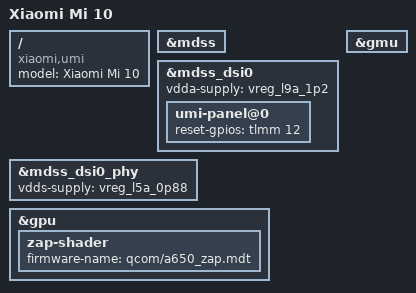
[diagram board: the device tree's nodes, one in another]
// SPDX-License-Identifier: BSD-3-Clause
/*
 * Xiaomi Mi 10 (umi / M2001J2C) — SM8250
 *
 * 阶段一（已完成）：内核能起来、USB 能枚举、COM3 拿到 root shell、UFS 6 个 LUN 全在。
 *   那时候故意不打开 mdss，让 simpledrm 接管 ABL 留下的 cont-splash，
 *   屏幕上能直接看到内核 log —— 没有 UART 时这是唯一可靠的观测手段。
 *
 * 阶段二（当前）：打开 mdss / DPU / DSI0 / 7nm PHY，验证显示子系统能 probe。
 *   ★ 面板节点（dts/xiaomi-umi-panels.dtsi）**默认不 include**。
 *     没有 panel 就：
 *       - devm_drm_of_get_bridge() 返回 -ENODEV
 *       - dsi_bind() 失败 -> msm master bind 失败 -> 不注册 card0
 *       - 因此不会做任何 modeset，屏幕上的 log 和以前完全一样
 *     但 DPU 的 dpu_kms_init()（读 catalog / 开 DISP_CC GDSC / 上 MMCX /
 *     读 MDP 寄存器）在 component_bind_all() **之前**就已经跑完了，
 *     所以这一次启动就能确认 mdss + DPU + DSI + PHY 的电源/时钟/寄存器通路。
 *
 * 阶段三：把文件末尾的 #include 取消注释，面板 status="okay" 但带 xiaomi,no-init，
 *   让 DSI 真正 attach 上去、connector 出现、card0 注册 —— 仍然一个字节都不发给面板。
 *
 * 阶段四：去掉 xiaomi,no-init，真正发 init 序列，亮度从 bl-min 起。
 *
 * 需要 GPU / PCIe-WiFi / 触摸 / 面板 的其它组合请看 sm8250-xiaomi-umi-plus.dts。
 */
/dts-v1/;

#include "sm8250-xiaomi-umi-common.dtsi"

/ {
	model = "Xiaomi Mi 10";
	compatible = "xiaomi,umi", "qcom,sm8250";
};

/* ---------------------------------------------------------------- 显示子系统 */

&mdss {
	status = "okay";
};

&mdss_dsi0 {
	/*
	 * ★ 这里**只**给 regulator 的引用，不给任何电压值。
	 *   两路轨在下游 DT 里都是固定值 + qcom,proxy-consumer-enable，
	 *   ABL 起来之后就已经是开的；主线这边 min == max 也写死成同一个值，
	 *   regulator_enable() 只发 enable 命令，改不了电压。
	 *
	 *   下游对照（dump/downstream.dts）：
	 *     qcom,mdss_dsi_ctrl0@ae94000  vdda-1p2-supply = <&pm8150_l9>  0x124f80 = 1.2V
	 *     qcom,mdss_dsi_phy0@ae94400   vdda-0p9-supply = <&pm8150_l5>  0xd6d80  = 0.88V
	 *   本 DT 里：
	 *     vreg_l9a_1p2   min=max=1200000  ✓
	 *     vreg_l5a_0p88  min=max= 880000  ✓
	 */
	vdda-supply = <&vreg_l9a_1p2>;
	status = "okay";
};

&mdss_dsi0_phy {
	vdds-supply = <&vreg_l5a_0p88>;
	status = "okay";
};

/*
 * 阶段三：面板节点接进来，但带 xiaomi,no-init。
 *
 *   面板驱动会 probe / 报 mode / 注册 backlight，DSI 会 attach 上去，
 *   &mdss_dsi0_out 也有了 remote-endpoint -> dsi_bind 能过 -> msm master 绑上
 *   -> DPU 初始化进去 -> card1 出现 -> fbdev 会做一次 modeset
 *   -> 真正去锁 DSI PLL、打开 DSI 链路。
 *   但是 prepare/enable 是空的：不发任何 DCS、不拉 reset、不写背光。
 *
 *   这一步要回答的是：DSI 链路和 PLL 到底能不能起来。
 *   （阶段二已经证明 mdss / DSI ctrl / 7nm PHY 能 probe，但 component_bind_all()
 *     在 msm_drm_kms_init() **之前**跑，所以没有 panel 时 DPU 根本没被初始化。）
 */
#include "xiaomi-umi-panels.dtsi"

/*
 * 复位脚：下游 `qcom,platform-reset-gpio = <&tlmm 0x0c 0x00>`（= GPIO12, active high），
 * `qcom,mdss-dsi-reset-sequence = <1 1 0 1 1 10>` 是 (电平 延时ms) 三组：
 * 先 1 保持 1ms、再 0 保持 1ms、最后 1 保持 10ms —— 也就是一个低脉冲复位。
 *
 * 驱动里的顺序是：拉低 assert_ms(1ms) -> 拉高 release_ms(10ms)，
 * 和上面的低脉冲等价。
 *
 * ★ GPIO12 在 TLMM NORTH tile，所以 sm8250-xiaomi-umi-common.dtsi 里专门把
 *   gpio-reserved-ranges 拆开让它保留下来（12 单独是能读能写的，
 *   见那里的注释）。拿不到的话驱动会退化成「无复位模式」，probe 不会失败。
 */
&mdss_dsi0 {
	umi-panel@0 {
		reset-gpios = <&tlmm 12 GPIO_ACTIVE_HIGH>;
	};
};

/* ---------------------------------------------------------------- GPU (Adreno 650) */

/*
 * GPU 需要的固件（都从本机 MIUI 的 /vendor/firmware 取，或 modem 分区）：
 *
 *   /lib/firmware/qcom/a650_zap.mdt   + a650_zap.b00/.b01/.b02
 *   /lib/firmware/qcom/a650_sqe.fw
 *   /lib/firmware/qcom/a650_gmu.bin
 *
 * 6.12 的 adreno 驱动用 qcom_mdt_load() 加载 zap：它会拿固件名末尾 3 个字符
 * 换成 "bXX" 去找分段（drivers/soc/qcom/mdt_loader.c:83），所以分段文件必须
 * 和 .mdt 同前缀。zap 的名字来自 a6xx_catalog.c 里的 .zapfw，DT 里的
 * firmware-name 只是给新内核留的兼容位。
 *
 * 缺固件时 adreno probe 会失败（-2/-22），显示（msm/mdss/dsi）不受影响。
 */
&gmu {
	status = "okay";
};

&gpu {
	status = "okay";

	zap-shader {
		firmware-name = "qcom/a650_zap.mdt";
	};
};

/*
 * 触摸：STMicroelectronics FTS（不是 goodix，虽然下游 DT 里两个节点都 status=ok，
 * 实机上 /proc/bus/input/devices 只有 "fts"，goodix@5d 从来没 bind 过）。
 *   - 总线 i2c@a94000 = 主线 &i2c13（QUPV3 wrap1 SE5），SDA/SCL = GPIO37/36
 *   - 地址 0x49，reset = GPIO38（active high），irq = GPIO39（level low）
 * 驱动 patches/fts-umi.c，不碰任何调压器、不烧固件。
 */
#include "sm8250-xiaomi-umi-touch.dtsi"
